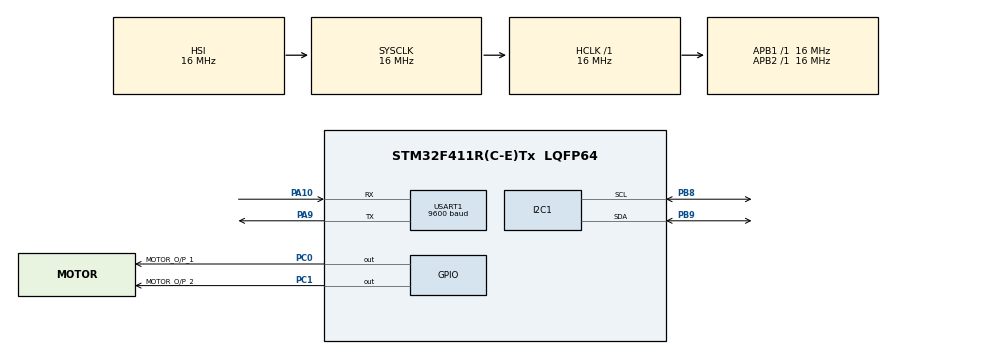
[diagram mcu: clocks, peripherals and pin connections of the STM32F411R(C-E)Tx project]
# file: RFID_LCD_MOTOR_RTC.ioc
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Mcu.Family=STM32F4
Mcu.Name=STM32F411R(C-E)Tx
Mcu.Package=LQFP64
NVIC.PriorityGroup=NVIC_PRIORITYGROUP_4
NVIC.RTC_Alarm_IRQn=true\:0\:0\:false\:false\:true\:true\:true\:true
NVIC.USART1_IRQn=true\:0\:0\:false\:false\:true\:true\:true\:true
PA10.Mode=Asynchronous
PA10.Signal=USART1_RX
PA9.Mode=Asynchronous
PA9.Signal=USART1_TX
PB8.Mode=I2C
PB8.Signal=I2C1_SCL
PB9.Mode=I2C
PB9.Signal=I2C1_SDA
PC0.GPIO_Label=MOTOR_O/P_1
PC0.Signal=GPIO_Output
PC1.GPIO_Label=MOTOR_O/P_2
PC1.Signal=GPIO_Output
ProjectManager.HeapSize=0x200
ProjectManager.StackSize=0x400
ProjectManager.TargetToolchain=STM32CubeIDE
RCC.AHBFreq_Value=16000000
RCC.APB1Freq_Value=16000000
RCC.APB2Freq_Value=16000000
RCC.CortexFreq_Value=16000000
RCC.HSE_VALUE=25000000
RCC.HSI_VALUE=16000000
RCC.LSE_VALUE=32768
RCC.SYSCLKFreq_VALUE=16000000
RCC.VCOOutputFreq_Value=192000000
RTC.Alarm=RTC_ALARM_A
RTC.Date=26
RTC.Format=RTC_FORMAT_BIN
RTC.Hours=15
RTC.Minutes=59
RTC.Month=RTC_MONTH_DECEMBER
RTC.Seconds=45
RTC.Seconds_A=10
RTC.Year=22
USART1.BaudRate=9600
USART1.VirtualMode=VM_ASYNC
VP_RTC_VS_RTC_Activate.Mode=RTC_Enabled
VP_RTC_VS_RTC_Alarm_A_Intern.Mode=Alarm A
VP_RTC_VS_RTC_Calendar.Mode=RTC_Calendar
board=custom

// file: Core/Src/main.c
/* USER CODE BEGIN Header */
/**
  ******************************************************************************
  * @file           : main.c
  * @brief          : Main program body
  ******************************************************************************
  * @attention
  *
  * Copyright (c) 2022 STMicroelectronics.
  * All rights reserved.
  *
  * This software is licensed under terms that can be found in the LICENSE file
  * in the root directory of this software component.
  * If no LICENSE file comes with this software, it is provided AS-IS.
  *
  ******************************************************************************
  */
/* USER CODE END Header */
#include "main.h"
#include<string.h>
#include"lcd.h"
#include "RTC.h"

I2C_HandleTypeDef hi2c1;

RTC_HandleTypeDef hrtc;

UART_HandleTypeDef huart1;

/* USER CODE BEGIN PV */
void GetTime_Init(void);
void MOTOR_Init(void);
//void GetTime_Init(void);
/* USER CODE END PV */

void SystemClock_Config(void);
static void MX_GPIO_Init(void);
static void MX_I2C1_Init(void);
static void MX_USART1_UART_Init(void);
static void MX_RTC_Init(void);
/* USER CODE BEGIN PFP */
#define TRUE 1
#define FALSE 0
/* USER CODE END PFP */

/* USER CODE BEGIN 0 */
char Time[10];
char Date[10];
/* USER CODE END 0 */
char *USER_DATA="Sankalp!";
uint8_t recvd_data;
	uint8_t data_buf[50];
	uint8_t count=0;
	uint8_t rec_comp_data=FALSE;
	char str[20];

int main(void)
{

  /* MCU Configuration--------------------------------------------------------*/

  /* Reset of all peripherals, Initializes the Flash interface and the Systick. */
  HAL_Init();

  /* Configure the system clock */
  SystemClock_Config();

  /* Initialize all configured peripherals */
  MX_GPIO_Init();
  MX_I2C1_Init();
  MX_USART1_UART_Init();
  MX_RTC_Init();

  /* Infinite loop */
	  while (1)
	  {

    /* USER CODE BEGIN 3 */
  uint16_t len_of_data=strlen(USER_DATA);
   HAL_UART_Transmit(&huart1, (uint8_t*)USER_DATA,len_of_data, HAL_MAX_DELAY);
   while(rec_comp_data != TRUE)
   {
 	  HAL_UART_Receive_IT(&huart1,&recvd_data,1);
   }
   while(1);
   return 0;
  /* USER CODE END 3 */
}

void SystemClock_Config(void)
{
  RCC_OscInitTypeDef RCC_OscInitStruct = {0};
  RCC_ClkInitTypeDef RCC_ClkInitStruct = {0};

  /** Configure the main internal regulator output voltage
  */
  __HAL_RCC_PWR_CLK_ENABLE();
  __HAL_PWR_VOLTAGESCALING_CONFIG(PWR_REGULATOR_VOLTAGE_SCALE1);

  /** Initializes the RCC Oscillators according to the specified parameters
  * in the RCC_OscInitTypeDef structure.
  */
  RCC_OscInitStruct.OscillatorType = RCC_OSCILLATORTYPE_HSI|RCC_OSCILLATORTYPE_LSI;
  RCC_OscInitStruct.HSIState = RCC_HSI_ON;
  RCC_OscInitStruct.HSICalibrationValue = RCC_HSICALIBRATION_DEFAULT;
  RCC_OscInitStruct.LSIState = RCC_LSI_ON;
  RCC_OscInitStruct.PLL.PLLState = RCC_PLL_NONE;
  if (HAL_RCC_OscConfig(&RCC_OscInitStruct) != HAL_OK)
  {
    Error_Handler();
  }

  /** Initializes the CPU, AHB and APB buses clocks
  */
  RCC_ClkInitStruct.ClockType = RCC_CLOCKTYPE_HCLK|RCC_CLOCKTYPE_SYSCLK
                              |RCC_CLOCKTYPE_PCLK1|RCC_CLOCKTYPE_PCLK2;
  RCC_ClkInitStruct.SYSCLKSource = RCC_SYSCLKSOURCE_HSI;
  RCC_ClkInitStruct.AHBCLKDivider = RCC_SYSCLK_DIV1;
  RCC_ClkInitStruct.APB1CLKDivider = RCC_HCLK_DIV1;
  RCC_ClkInitStruct.APB2CLKDivider = RCC_HCLK_DIV1;

  if (HAL_RCC_ClockConfig(&RCC_ClkInitStruct, FLASH_LATENCY_0) != HAL_OK)
  {
    Error_Handler();
  }
}

static void MX_I2C1_Init(void)
{

  hi2c1.Instance = I2C1;
  hi2c1.Init.ClockSpeed = 100000;
  hi2c1.Init.DutyCycle = I2C_DUTYCYCLE_2;
  hi2c1.Init.OwnAddress1 = 0;
  hi2c1.Init.AddressingMode = I2C_ADDRESSINGMODE_7BIT;
  hi2c1.Init.DualAddressMode = I2C_DUALADDRESS_DISABLE;
  hi2c1.Init.OwnAddress2 = 0;
  hi2c1.Init.GeneralCallMode = I2C_GENERALCALL_DISABLE;
  hi2c1.Init.NoStretchMode = I2C_NOSTRETCH_DISABLE;
  if (HAL_I2C_Init(&hi2c1) != HAL_OK)
  {
    Error_Handler();
  }

}

static void MX_RTC_Init(void)
{

  RTC_TimeTypeDef sTime = {0};
  RTC_DateTypeDef sDate = {0};
  RTC_AlarmTypeDef sAlarm = {0};

  /** Initialize RTC Only
  */
  hrtc.Instance = RTC;
  hrtc.Init.HourFormat = RTC_HOURFORMAT_24;
  hrtc.Init.AsynchPrediv = 127;
  hrtc.Init.SynchPrediv = 255;
  hrtc.Init.OutPut = RTC_OUTPUT_DISABLE;
  hrtc.Init.OutPutPolarity = RTC_OUTPUT_POLARITY_HIGH;
  hrtc.Init.OutPutType = RTC_OUTPUT_TYPE_OPENDRAIN;
  if (HAL_RTC_Init(&hrtc) != HAL_OK)
  {
    Error_Handler();
  }

  /** Initialize RTC and set the Time and Date
  */
  sTime.Hours = 15;
  sTime.Minutes = 59;
  sTime.Seconds = 45;
  sTime.DayLightSaving = RTC_DAYLIGHTSAVING_NONE;
  sTime.StoreOperation = RTC_STOREOPERATION_RESET;
  if (HAL_RTC_SetTime(&hrtc, &sTime, RTC_FORMAT_BIN) != HAL_OK)
  {
    Error_Handler();
  }
  sDate.WeekDay = RTC_WEEKDAY_MONDAY;
  sDate.Month = RTC_MONTH_DECEMBER;
  sDate.Date = 26;
  sDate.Year = 22;

  if (HAL_RTC_SetDate(&hrtc, &sDate, RTC_FORMAT_BIN) != HAL_OK)
  {
    Error_Handler();
  }

  /** Enable the Alarm A
  */
  sAlarm.AlarmTime.Hours = 0;
  sAlarm.AlarmTime.Minutes = 0;
  sAlarm.AlarmTime.Seconds = 10;
  sAlarm.AlarmTime.SubSeconds = 0;
  sAlarm.AlarmTime.DayLightSaving = RTC_DAYLIGHTSAVING_NONE;
  sAlarm.AlarmTime.StoreOperation = RTC_STOREOPERATION_RESET;
  sAlarm.AlarmMask = RTC_ALARMMASK_NONE;
  sAlarm.AlarmSubSecondMask = RTC_ALARMSUBSECONDMASK_ALL;
  sAlarm.AlarmDateWeekDaySel = RTC_ALARMDATEWEEKDAYSEL_DATE;
  sAlarm.AlarmDateWeekDay = 1;
  sAlarm.Alarm = RTC_ALARM_A;
  if (HAL_RTC_SetAlarm_IT(&hrtc, &sAlarm, RTC_FORMAT_BIN) != HAL_OK)
  {
    Error_Handler();
  }

}

static void MX_USART1_UART_Init(void)
{

  huart1.Instance = USART1;
  huart1.Init.BaudRate = 9600;
  huart1.Init.WordLength = UART_WORDLENGTH_8B;
  huart1.Init.StopBits = UART_STOPBITS_1;
  huart1.Init.Parity = UART_PARITY_NONE;
  huart1.Init.Mode = UART_MODE_TX_RX;
  huart1.Init.HwFlowCtl = UART_HWCONTROL_NONE;
  huart1.Init.OverSampling = UART_OVERSAMPLING_16;
  if (HAL_UART_Init(&huart1) != HAL_OK)
  {
    Error_Handler();
  }

}

static void MX_GPIO_Init(void)
{
  GPIO_InitTypeDef GPIO_InitStruct = {0};

  /* GPIO Ports Clock Enable */
  __HAL_RCC_GPIOC_CLK_ENABLE();
  __HAL_RCC_GPIOA_CLK_ENABLE();
  __HAL_RCC_GPIOB_CLK_ENABLE();

  /*Configure GPIO pin Output Level */
  HAL_GPIO_WritePin(GPIOC, MOTOR_O_P_1_Pin|MOTOR_O_P_2_Pin, GPIO_PIN_RESET);

  /*Configure GPIO pins : MOTOR_O_P_1_Pin MOTOR_O_P_2_Pin */
  GPIO_InitStruct.Pin = MOTOR_O_P_1_Pin|MOTOR_O_P_2_Pin;
  GPIO_InitStruct.Mode = GPIO_MODE_OUTPUT_PP;
  GPIO_InitStruct.Pull = GPIO_NOPULL;
  GPIO_InitStruct.Speed = GPIO_SPEED_FREQ_LOW;
  HAL_GPIO_Init(GPIOC, &GPIO_InitStruct);

}

void Error_Handler(void)
{
  __disable_irq();
  while (1)
  {
  }
}
